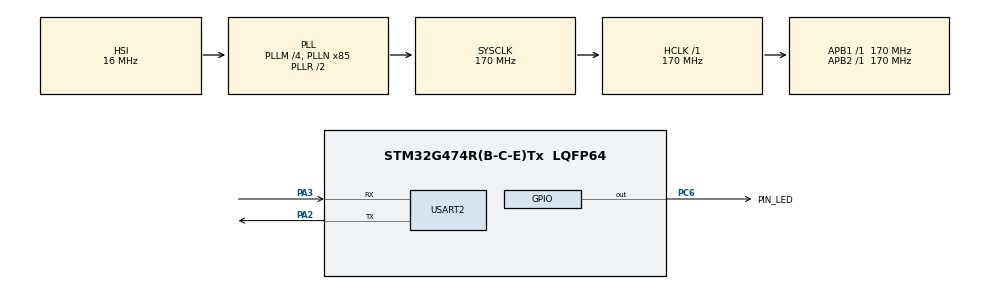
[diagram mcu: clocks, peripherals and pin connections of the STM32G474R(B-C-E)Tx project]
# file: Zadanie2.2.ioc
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Dma.Request0=USART2_RX
Dma.USART2_RX.0.Direction=DMA_PERIPH_TO_MEMORY
Dma.USART2_RX.0.EventEnable=DISABLE
Dma.USART2_RX.0.Instance=DMA1_Channel1
Dma.USART2_RX.0.MemDataAlignment=DMA_MDATAALIGN_BYTE
Dma.USART2_RX.0.MemInc=DMA_MINC_ENABLE
Dma.USART2_RX.0.Mode=DMA_NORMAL
Dma.USART2_RX.0.PeriphDataAlignment=DMA_PDATAALIGN_BYTE
Dma.USART2_RX.0.PeriphInc=DMA_PINC_DISABLE
Dma.USART2_RX.0.Polarity=HAL_DMAMUX_REQ_GEN_RISING
Dma.USART2_RX.0.Priority=DMA_PRIORITY_LOW
Dma.USART2_RX.0.RequestNumber=1
Dma.USART2_RX.0.SignalID=NONE
Dma.USART2_RX.0.SyncEnable=DISABLE
Dma.USART2_RX.0.SyncPolarity=HAL_DMAMUX_SYNC_NO_EVENT
Dma.USART2_RX.0.SyncRequestNumber=1
Dma.USART2_RX.0.SyncSignalID=NONE
Mcu.Family=STM32G4
Mcu.Name=STM32G474R(B-C-E)Tx
Mcu.Package=LQFP64
NVIC.DMA1_Channel1_IRQn=true\:0\:0\:false\:false\:true\:false\:true\:true
NVIC.PriorityGroup=NVIC_PRIORITYGROUP_4
NVIC.USART2_IRQn=true\:0\:0\:false\:false\:true\:true\:true\:true
PA2.Mode=Asynchronous
PA2.Signal=USART2_TX
PA3.Mode=Asynchronous
PA3.Signal=USART2_RX
PC6.GPIO_Label=PIN_LED
PC6.Signal=GPIO_Output
ProjectManager.HeapSize=0x200
ProjectManager.StackSize=0x1000
ProjectManager.TargetToolchain=CMake
RCC.ADC12Freq_Value=170000000
RCC.ADC345Freq_Value=170000000
RCC.AHBFreq_Value=170000000
RCC.APB1Freq_Value=170000000
RCC.APB1TimFreq_Value=170000000
RCC.APB2Freq_Value=170000000
RCC.APB2TimFreq_Value=170000000
RCC.CortexFreq_Value=170000000
RCC.EXTERNAL_CLOCK_VALUE=12288000
RCC.HCLKFreq_Value=170000000
RCC.HSE_VALUE=8000000
RCC.HSI48_VALUE=48000000
RCC.HSI_VALUE=16000000
RCC.LSE_VALUE=32768
RCC.PLLM=RCC_PLLM_DIV4
RCC.PLLN=85
RCC.SYSCLKFreq_VALUE=170000000
RCC.SYSCLKSource=RCC_SYSCLKSOURCE_PLLCLK
RCC.USBFreq_Value=170000000
RCC.VCOOutputFreq_Value=340000000
USART2.VirtualMode-Asynchronous=VM_ASYNC
VP_SYS_VS_DBSignals.Mode=DisableDeadBatterySignals
board=custom

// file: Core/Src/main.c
/* USER CODE BEGIN Header */
/**
  ******************************************************************************
  * @file           : main.c
  * @brief          : Main program body
  ******************************************************************************
  * @attention
  *
  * Copyright (c) 2025 STMicroelectronics.
  * All rights reserved.
  *
  * This software is licensed under terms that can be found in the LICENSE file
  * in the root directory of this software component.
  * If no LICENSE file comes with this software, it is provided AS-IS.
  *
  ******************************************************************************
  */
/* USER CODE END Header */
#include "main.h"

/* USER CODE BEGIN Includes */
#include "Z2_Lib.h"
#include <stdio.h>
/* USER CODE END Includes */

UART_HandleTypeDef huart2;
DMA_HandleTypeDef hdma_usart2_rx;

/* USER CODE BEGIN PV */

Z2_COMMANDS_VARIABLE

#define BUFF_SIZE 512
static char buff[BUFF_SIZE];

void HAL_UARTEx_RxEventCallback(UART_HandleTypeDef *huart, uint16_t Size)
{
	static const char* response = "command received\n";
	static const char* responseError = "command not found\n";
	switch (Z2_ExecuteCommand(buff, Size))
	{
	case 0:
		HAL_UART_Transmit(&huart2, (const uint8_t*)response, strlen(response), 300);
		break;
	default:
		HAL_UART_Transmit(&huart2, (const uint8_t*)responseError, strlen(responseError), 300);
	}

	HAL_UARTEx_ReceiveToIdle_DMA(&huart2, (uint8_t*)buff, BUFF_SIZE);
}

static int blinkT = 500;
static float blinkHT = 200;

void BlinkStop()
{
	blinkHT = 0;
}

void BlinkStringInt()
{
	blinkT = Z2_GetArg_Int(1);
}

void Blink2()
{
	blinkT = Z2_GetArg_Int(1);
	blinkHT = Z2_GetArg_Float(2);
	const char* message3 = Z2_GetArg_String(3);
	const char* message = Z2_GetArg_String(0);
	HAL_UART_Transmit(&huart2, (const uint8_t*)message3, strlen(message3), 300);
	HAL_UART_Transmit(&huart2, (const uint8_t*)message, strlen(message), 300);
}

void Help()
{
	// This could be done better with a circular DMA or something, but this works
	sprintf(buff, "\n-------------------------------\nThere are %d commands:\n", z2_Commands->registeredCommandsNum);
	HAL_UART_Transmit(&huart2, (const uint8_t*)buff, strlen(buff), 300);
	for (int comI = 0; comI < z2_Commands->registeredCommandsNum; ++comI)
	{
		sprintf(buff, "\t%s[=", z2_Commands->commands[comI].name);
		HAL_UART_Transmit(&huart2, (const uint8_t*)buff, strlen(buff), 300);
		for (int argI = 0; argI < z2_Commands->commands[comI].argCount; ++argI)
		{
			sprintf(buff, "%s (%s);", z2_Commands->commands[comI].args[argI].name, Z2_ArgTypeToString(z2_Commands->commands[comI].args[argI].type));
			HAL_UART_Transmit(&huart2, (const uint8_t*)buff, strlen(buff), 300);
		}
		sprintf(buff, "]\n");
		HAL_UART_Transmit(&huart2, (const uint8_t*)buff, strlen(buff), 300);
	}
	sprintf(buff, "\n-------------------------------\n");
	HAL_UART_Transmit(&huart2, (const uint8_t*)buff, strlen(buff), 300);
}
/* USER CODE END PV */

void SystemClock_Config(void);
static void MX_GPIO_Init(void);
static void MX_DMA_Init(void);
static void MX_USART2_UART_Init(void);

int main(void)
{

  /* MCU Configuration--------------------------------------------------------*/

  /* Reset of all peripherals, Initializes the Flash interface and the Systick. */
  HAL_Init();

  /* Configure the system clock */
  SystemClock_Config();

  /* Initialize all configured peripherals */
  MX_GPIO_Init();
  MX_DMA_Init();
  MX_USART2_UART_Init();
  /* USER CODE BEGIN 2 */

  HAL_GPIO_WritePin(PIN_LED_GPIO_Port, PIN_LED_Pin, 1);
  HAL_UARTEx_ReceiveToIdle_DMA(&huart2, (uint8_t*)buff, BUFF_SIZE);

  Z2_CREATE_COMMANDS(4);
  Z2_REGISTER_COMMAND("help", &Help);
  Z2_REGISTER_COMMAND("don't blink", &BlinkStop);
  Z2_REGISTER_COMMAND_ARGS("blink string int", &BlinkStringInt, 2, "tekst", Z2_ArgString, "okres", Z2_ArgInt);
  Z2_REGISTER_COMMAND_ARGS("blink2", &Blink2, 4, "tekst", Z2_ArgString,"okres", Z2_ArgInt, "czas swiecenia", Z2_ArgFloat, "tekst", Z2_ArgString);

  /* USER CODE END 2 */

  /* Infinite loop */
  /* USER CODE BEGIN WHILE */
  while (1)
  {
	  HAL_GPIO_WritePin(PIN_LED_GPIO_Port, PIN_LED_Pin, HAL_GetTick() % blinkT < blinkHT);
    /* USER CODE END WHILE */

  }
}

void SystemClock_Config(void)
{
  RCC_OscInitTypeDef RCC_OscInitStruct = {0};
  RCC_ClkInitTypeDef RCC_ClkInitStruct = {0};

  /** Configure the main internal regulator output voltage
  */
  HAL_PWREx_ControlVoltageScaling(PWR_REGULATOR_VOLTAGE_SCALE1_BOOST);

  /** Initializes the RCC Oscillators according to the specified parameters
  * in the RCC_OscInitTypeDef structure.
  */
  RCC_OscInitStruct.OscillatorType = RCC_OSCILLATORTYPE_HSI;
  RCC_OscInitStruct.HSIState = RCC_HSI_ON;
  RCC_OscInitStruct.HSICalibrationValue = RCC_HSICALIBRATION_DEFAULT;
  RCC_OscInitStruct.PLL.PLLState = RCC_PLL_ON;
  RCC_OscInitStruct.PLL.PLLSource = RCC_PLLSOURCE_HSI;
  RCC_OscInitStruct.PLL.PLLM = RCC_PLLM_DIV4;
  RCC_OscInitStruct.PLL.PLLN = 85;
  RCC_OscInitStruct.PLL.PLLP = RCC_PLLP_DIV2;
  RCC_OscInitStruct.PLL.PLLQ = RCC_PLLQ_DIV2;
  RCC_OscInitStruct.PLL.PLLR = RCC_PLLR_DIV2;
  if (HAL_RCC_OscConfig(&RCC_OscInitStruct) != HAL_OK)
  {
    Error_Handler();
  }

  /** Initializes the CPU, AHB and APB buses clocks
  */
  RCC_ClkInitStruct.ClockType = RCC_CLOCKTYPE_HCLK|RCC_CLOCKTYPE_SYSCLK
                              |RCC_CLOCKTYPE_PCLK1|RCC_CLOCKTYPE_PCLK2;
  RCC_ClkInitStruct.SYSCLKSource = RCC_SYSCLKSOURCE_PLLCLK;
  RCC_ClkInitStruct.AHBCLKDivider = RCC_SYSCLK_DIV1;
  RCC_ClkInitStruct.APB1CLKDivider = RCC_HCLK_DIV1;
  RCC_ClkInitStruct.APB2CLKDivider = RCC_HCLK_DIV1;

  if (HAL_RCC_ClockConfig(&RCC_ClkInitStruct, FLASH_LATENCY_4) != HAL_OK)
  {
    Error_Handler();
  }
}

static void MX_USART2_UART_Init(void)
{

  huart2.Instance = USART2;
  huart2.Init.BaudRate = 115200;
  huart2.Init.WordLength = UART_WORDLENGTH_8B;
  huart2.Init.StopBits = UART_STOPBITS_1;
  huart2.Init.Parity = UART_PARITY_NONE;
  huart2.Init.Mode = UART_MODE_TX_RX;
  huart2.Init.HwFlowCtl = UART_HWCONTROL_NONE;
  huart2.Init.OverSampling = UART_OVERSAMPLING_16;
  huart2.Init.OneBitSampling = UART_ONE_BIT_SAMPLE_DISABLE;
  huart2.Init.ClockPrescaler = UART_PRESCALER_DIV1;
  huart2.AdvancedInit.AdvFeatureInit = UART_ADVFEATURE_NO_INIT;
  if (HAL_UART_Init(&huart2) != HAL_OK)
  {
    Error_Handler();
  }
  if (HAL_UARTEx_SetTxFifoThreshold(&huart2, UART_TXFIFO_THRESHOLD_1_8) != HAL_OK)
  {
    Error_Handler();
  }
  if (HAL_UARTEx_SetRxFifoThreshold(&huart2, UART_RXFIFO_THRESHOLD_1_8) != HAL_OK)
  {
    Error_Handler();
  }
  if (HAL_UARTEx_DisableFifoMode(&huart2) != HAL_OK)
  {
    Error_Handler();
  }

}

static void MX_DMA_Init(void)
{

  /* DMA controller clock enable */
  __HAL_RCC_DMAMUX1_CLK_ENABLE();
  __HAL_RCC_DMA1_CLK_ENABLE();

  /* DMA interrupt init */
  /* DMA1_Channel1_IRQn interrupt configuration */
  HAL_NVIC_SetPriority(DMA1_Channel1_IRQn, 0, 0);
  HAL_NVIC_EnableIRQ(DMA1_Channel1_IRQn);

}

static void MX_GPIO_Init(void)
{
  GPIO_InitTypeDef GPIO_InitStruct = {0};

  /* GPIO Ports Clock Enable */
  __HAL_RCC_GPIOA_CLK_ENABLE();
  __HAL_RCC_GPIOC_CLK_ENABLE();

  /*Configure GPIO pin Output Level */
  HAL_GPIO_WritePin(PIN_LED_GPIO_Port, PIN_LED_Pin, GPIO_PIN_RESET);

  /*Configure GPIO pin : PIN_LED_Pin */
  GPIO_InitStruct.Pin = PIN_LED_Pin;
  GPIO_InitStruct.Mode = GPIO_MODE_OUTPUT_PP;
  GPIO_InitStruct.Pull = GPIO_NOPULL;
  GPIO_InitStruct.Speed = GPIO_SPEED_FREQ_LOW;
  HAL_GPIO_Init(PIN_LED_GPIO_Port, &GPIO_InitStruct);

}

void Error_Handler(void)
{
  __disable_irq();
  while (1)
  {
  }
}
